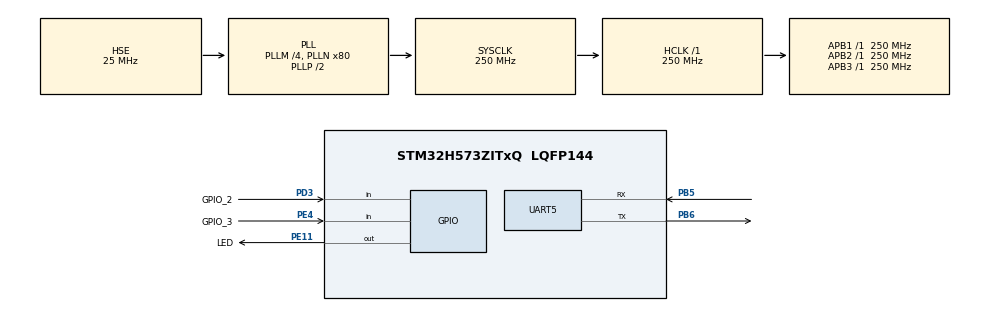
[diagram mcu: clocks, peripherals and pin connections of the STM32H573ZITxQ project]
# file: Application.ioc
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BOOTPATH.BootPathName=LEGACY
BOOTPATH.UserSelectedBootPath=LEGACY
CORTEX_M33_NS.userName=CORTEX_M33
Mcu.Family=STM32H5
Mcu.Name=STM32H573ZITxQ
Mcu.Package=LQFP144
NVIC.PriorityGroup=NVIC_PRIORITYGROUP_4
NVIC.UART5_IRQn=true\:0\:0\:false\:false\:true\:true\:true\:true
PB5.Mode=Asynchronous
PB5.Signal=UART5_RX
PB6.Mode=Asynchronous
PB6.Signal=UART5_TX
PC14-OSC32_IN(OSC32_IN).Mode=LSE-External-Oscillator
PC14-OSC32_IN(OSC32_IN).Signal=RCC_OSC32_IN
PC15-OSC32_OUT(OSC32_OUT).Mode=LSE-External-Oscillator
PC15-OSC32_OUT(OSC32_OUT).Signal=RCC_OSC32_OUT
PD3.GPIO_Label=GPIO_2
PD3.Signal=GPIO_Input
PE11.GPIO_Label=LED
PE11.Signal=GPIO_Output
PE4.GPIO_Label=GPIO_3
PE4.Signal=GPIO_Input
PH0-OSC_IN(PH0).Mode=HSE-External-Oscillator
PH0-OSC_IN(PH0).Signal=RCC_OSC_IN
PH1-OSC_OUT(PH1).Mode=HSE-External-Oscillator
PH1-OSC_OUT(PH1).Signal=RCC_OSC_OUT
ProjectManager.HeapSize=0x200
ProjectManager.StackSize=0x400
ProjectManager.TargetToolchain=STM32CubeIDE
RCC.ADCFreq_Value=250000000
RCC.AHBFreq_Value=250000000
RCC.APB1Freq_Value=250000000
RCC.APB1TimFreq_Value=250000000
RCC.APB2Freq_Value=250000000
RCC.APB2TimFreq_Value=250000000
RCC.APB3Freq_Value=250000000
RCC.CSI_VALUE=4000000
RCC.CortexFreq_Value=250000000
RCC.EPOD_VALUE=25000000
RCC.HCLKFreq_Value=250000000
RCC.HSE_VALUE=25000000
RCC.HSI48_VALUE=48000000
RCC.HSI_VALUE=64000000
RCC.LSIRC_VALUE=32000
RCC.PLLFRACN=0
RCC.PLLM=4
RCC.PLLN=80
RCC.PLLSourceVirtual=RCC_PLL1_SOURCE_HSE
RCC.SYSCLKFreq_VALUE=250000000
RCC.SYSCLKSource=RCC_SYSCLKSOURCE_PLLCLK
RCC.USBFreq_Value=48000000
RCC.VCOOutputFreq_Value=500000000
VP_BOOTPATH_VS_BOOTPATH.Mode=BP_Activate
VP_CORTEX_M33_NS_VS_Hclk.Mode=Hclk_Mode
VP_ICACHE_VS_ENABLE_ICACHE_MEMORY.Mode=Memoryregions
VP_MEMORYMAP_VS_MEMORYMAP.Mode=CurAppReg
VP_PWR_VS_DBSignals.Mode=DisableDeadBatterySignals
VP_PWR_VS_LPOM.Mode=PowerOptimisation
VP_PWR_VS_SECSignals.Mode=Security/Privilege
board=custom

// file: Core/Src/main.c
/* USER CODE BEGIN Header */
/**
 ******************************************************************************
 * @file           : main.c
 * @brief          : Main program body
 ******************************************************************************
 * @attention
 *
 * Copyright (c) 2024 STMicroelectronics.
 * All rights reserved.
 *
 * This software is licensed under terms that can be found in the LICENSE file
 * in the root directory of this software component.
 * If no LICENSE file comes with this software, it is provided AS-IS.
 *
 ******************************************************************************
 */
/* USER CODE END Header */
#include "main.h"

/* USER CODE BEGIN Includes */
#include "stm32h5xx_hal_flash.h"
#include <string.h>
#include <stdbool.h>
/* USER CODE END Includes */

UART_HandleTypeDef huart5;

void SystemClock_Config(void);
static void MX_GPIO_Init(void);
static void MX_UART5_Init(void);

/* USER CODE BEGIN 0 */

// Function prototypes
void SystemClock_Config(void);
void Error_Handler(void);
/* USER CODE END 0 */

int main(void)
{

  /* MCU Configuration--------------------------------------------------------*/

  /* Reset of all peripherals, Initializes the Flash interface and the Systick. */
  HAL_Init();

  /* Configure the system clock */
  SystemClock_Config();

  /* Initialize all configured peripherals */
  MX_GPIO_Init();
  MX_UART5_Init();
  /* USER CODE BEGIN 2 */

	char *c_char = "Application hbjhgjhgfgfgjhgjhis Running... \n\r";
  /* USER CODE END 2 */

  /* Infinite loop */
	while (1)
	{

    /* USER CODE BEGIN 3 */

		HAL_UART_Transmit(&huart5,(uint8_t *)&c_char[0], strlen("Application hbjhgjhgfgfgjhgjhis Running... \n\r"), 1000);
		HAL_Delay(100);
	}
  /* USER CODE END 3 */
}

void SystemClock_Config(void)
{
  RCC_OscInitTypeDef RCC_OscInitStruct = {0};
  RCC_ClkInitTypeDef RCC_ClkInitStruct = {0};

  /** Configure the main internal regulator output voltage
  */
  __HAL_PWR_VOLTAGESCALING_CONFIG(PWR_REGULATOR_VOLTAGE_SCALE0);

  while(!__HAL_PWR_GET_FLAG(PWR_FLAG_VOSRDY)) {}

  /** Initializes the RCC Oscillators according to the specified parameters
  * in the RCC_OscInitTypeDef structure.
  */
  RCC_OscInitStruct.OscillatorType = RCC_OSCILLATORTYPE_HSE;
  RCC_OscInitStruct.HSEState = RCC_HSE_ON;
  RCC_OscInitStruct.PLL.PLLState = RCC_PLL_ON;
  RCC_OscInitStruct.PLL.PLLSource = RCC_PLL1_SOURCE_HSE;
  RCC_OscInitStruct.PLL.PLLM = 4;
  RCC_OscInitStruct.PLL.PLLN = 80;
  RCC_OscInitStruct.PLL.PLLP = 2;
  RCC_OscInitStruct.PLL.PLLQ = 2;
  RCC_OscInitStruct.PLL.PLLR = 2;
  RCC_OscInitStruct.PLL.PLLRGE = RCC_PLL1_VCIRANGE_2;
  RCC_OscInitStruct.PLL.PLLVCOSEL = RCC_PLL1_VCORANGE_WIDE;
  RCC_OscInitStruct.PLL.PLLFRACN = 0;
  if (HAL_RCC_OscConfig(&RCC_OscInitStruct) != HAL_OK)
  {
    Error_Handler();
  }

  /** Initializes the CPU, AHB and APB buses clocks
  */
  RCC_ClkInitStruct.ClockType = RCC_CLOCKTYPE_HCLK|RCC_CLOCKTYPE_SYSCLK
                              |RCC_CLOCKTYPE_PCLK1|RCC_CLOCKTYPE_PCLK2
                              |RCC_CLOCKTYPE_PCLK3;
  RCC_ClkInitStruct.SYSCLKSource = RCC_SYSCLKSOURCE_PLLCLK;
  RCC_ClkInitStruct.AHBCLKDivider = RCC_SYSCLK_DIV1;
  RCC_ClkInitStruct.APB1CLKDivider = RCC_HCLK_DIV1;
  RCC_ClkInitStruct.APB2CLKDivider = RCC_HCLK_DIV1;
  RCC_ClkInitStruct.APB3CLKDivider = RCC_HCLK_DIV1;

  if (HAL_RCC_ClockConfig(&RCC_ClkInitStruct, FLASH_LATENCY_5) != HAL_OK)
  {
    Error_Handler();
  }

  /** Configure the programming delay
  */
  __HAL_FLASH_SET_PROGRAM_DELAY(FLASH_PROGRAMMING_DELAY_2);
}

static void MX_UART5_Init(void)
{

  huart5.Instance = UART5;
  huart5.Init.BaudRate = 115200;
  huart5.Init.WordLength = UART_WORDLENGTH_8B;
  huart5.Init.StopBits = UART_STOPBITS_1;
  huart5.Init.Parity = UART_PARITY_NONE;
  huart5.Init.Mode = UART_MODE_TX_RX;
  huart5.Init.HwFlowCtl = UART_HWCONTROL_NONE;
  huart5.Init.OverSampling = UART_OVERSAMPLING_16;
  huart5.Init.OneBitSampling = UART_ONE_BIT_SAMPLE_DISABLE;
  huart5.Init.ClockPrescaler = UART_PRESCALER_DIV1;
  huart5.AdvancedInit.AdvFeatureInit = UART_ADVFEATURE_NO_INIT;
  if (HAL_UART_Init(&huart5) != HAL_OK)
  {
    Error_Handler();
  }
  if (HAL_UARTEx_SetTxFifoThreshold(&huart5, UART_TXFIFO_THRESHOLD_1_8) != HAL_OK)
  {
    Error_Handler();
  }
  if (HAL_UARTEx_SetRxFifoThreshold(&huart5, UART_RXFIFO_THRESHOLD_1_8) != HAL_OK)
  {
    Error_Handler();
  }
  if (HAL_UARTEx_DisableFifoMode(&huart5) != HAL_OK)
  {
    Error_Handler();
  }

}

static void MX_GPIO_Init(void)
{
  GPIO_InitTypeDef GPIO_InitStruct = {0};

  /* GPIO Ports Clock Enable */
  __HAL_RCC_GPIOE_CLK_ENABLE();
  __HAL_RCC_GPIOC_CLK_ENABLE();
  __HAL_RCC_GPIOH_CLK_ENABLE();
  __HAL_RCC_GPIOD_CLK_ENABLE();
  __HAL_RCC_GPIOB_CLK_ENABLE();

  /*Configure GPIO pin Output Level */
  HAL_GPIO_WritePin(LED_GPIO_Port, LED_Pin, GPIO_PIN_RESET);

  /*Configure GPIO pin : GPIO_3_Pin */
  GPIO_InitStruct.Pin = GPIO_3_Pin;
  GPIO_InitStruct.Mode = GPIO_MODE_INPUT;
  GPIO_InitStruct.Pull = GPIO_NOPULL;
  HAL_GPIO_Init(GPIO_3_GPIO_Port, &GPIO_InitStruct);

  /*Configure GPIO pin : LED_Pin */
  GPIO_InitStruct.Pin = LED_Pin;
  GPIO_InitStruct.Mode = GPIO_MODE_OUTPUT_PP;
  GPIO_InitStruct.Pull = GPIO_NOPULL;
  GPIO_InitStruct.Speed = GPIO_SPEED_FREQ_LOW;
  HAL_GPIO_Init(LED_GPIO_Port, &GPIO_InitStruct);

  /*Configure GPIO pin : GPIO_2_Pin */
  GPIO_InitStruct.Pin = GPIO_2_Pin;
  GPIO_InitStruct.Mode = GPIO_MODE_INPUT;
  GPIO_InitStruct.Pull = GPIO_NOPULL;
  HAL_GPIO_Init(GPIO_2_GPIO_Port, &GPIO_InitStruct);

}

void Error_Handler(void)
{
	__disable_irq();
	while (1)
	{
	}
}
